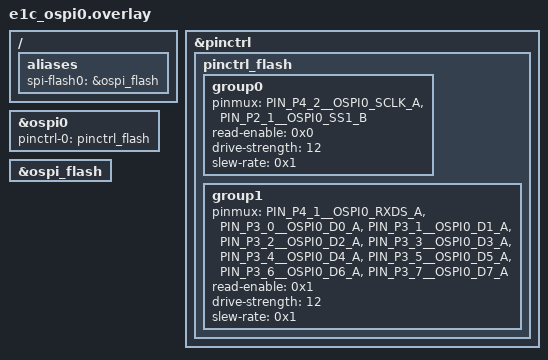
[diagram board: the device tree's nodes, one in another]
/* Copyright (C) 2026 Alif Semiconductor - All Rights Reserved.
 * Use, distribution and modification of this code is permitted under the
 * terms stated in the Alif Semiconductor Software License Agreement
 *
 * You should have received a copy of the Alif Semiconductor Software
 * License Agreement with this file. If not, please write to:
 * contact@alifsemi.com, or visit: https://alifsemi.com/license
 */

/*
 * OSPI0 Test with Flash
 */
/{
	aliases {
		spi-flash0 = &ospi_flash;
	};
};

&pinctrl {
	pinctrl_flash:pinctrl_flash {
		group0 {
			pinmux = <PIN_P4_2__OSPI0_SCLK_A>,
				 <PIN_P2_1__OSPI0_SS1_B>;
			read-enable = <0x0>;
			drive-strength = <12>;
			slew-rate = <0x1>;
		};
		group1 {
			pinmux = <PIN_P4_1__OSPI0_RXDS_A>,
				 <PIN_P3_0__OSPI0_D0_A>,
				 <PIN_P3_1__OSPI0_D1_A>,
				 <PIN_P3_2__OSPI0_D2_A>,
				 <PIN_P3_3__OSPI0_D3_A>,
				 <PIN_P3_4__OSPI0_D4_A>,
				 <PIN_P3_5__OSPI0_D5_A>,
				 <PIN_P3_6__OSPI0_D6_A>,
				 <PIN_P3_7__OSPI0_D7_A>;
			read-enable = <0x1>;
			drive-strength = <12>;
			slew-rate = <0x1>;
		};
	};
};

&ospi0 {
	pinctrl-0 = <&pinctrl_flash>;
	status = "okay";
};

&ospi_flash {
	status = "okay";
};
